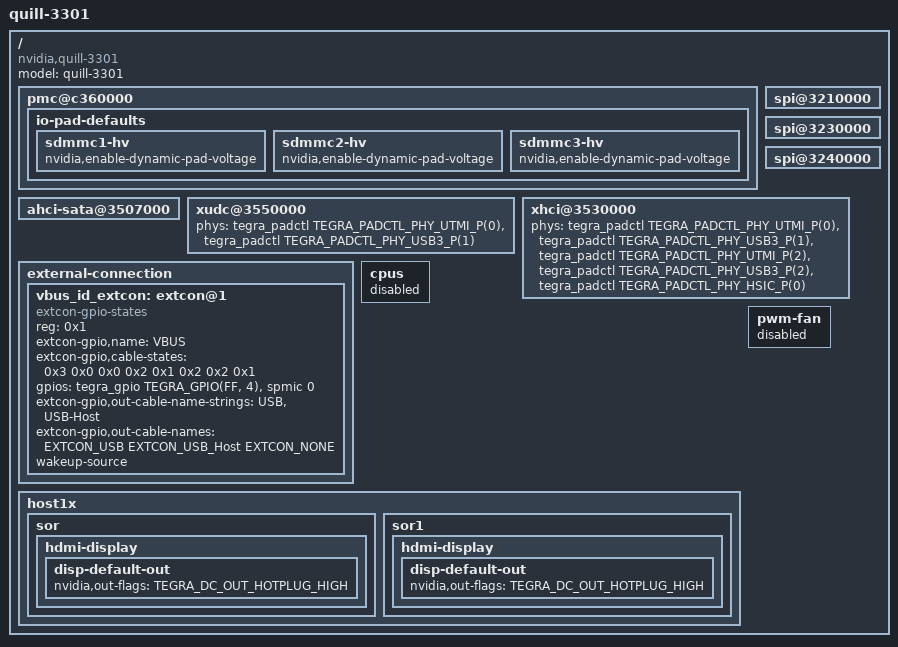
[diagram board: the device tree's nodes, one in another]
/*
 * tegra186-quill-comon-e3301-0000-a00.dtsi: Quill common dtsi.
 *
 * Copyright (c) 2015-2016, NVIDIA CORPORATION.  All rights reserved.
 *
 * This program is free software; you can redistribute it and/or modify
 * it under the terms of the GNU General Public License as published by
 * the Free Software Foundation; version 2 of the License.
 *
 * This program is distributed in the hope that it will be useful, but WITHOUT
 * ANY WARRANTY; without even the implied warranty of MERCHANTABILITY or
 * FITNESS FOR A PARTICULAR PURPOSE.  See the GNU General Public License for
 * more details.
 */

#include "tegra186-quill-common.dtsi"
#include "tegra186-quill-e3301-powermon.dtsi"
#include "tegra186-quill-pb-e3301-0000-a00-pinmux-manual.dtsi"
#include "tegra186-quill-pb-thermal.dtsi"

#define EXTCON_NONE		0
#define EXTCON_USB             1
#define EXTCON_USB_Host        2

/ {
        model = "quill-3301";
        compatible = "nvidia,quill-3301", "nvidia,tegra186";

        #address-cells = <2>;
        #size-cells = <2>;

	pmc@c360000 {
		io-pad-defaults {
			sdmmc1-hv {
				nvidia,enable-dynamic-pad-voltage;
			};
			sdmmc2-hv {
				nvidia,enable-dynamic-pad-voltage;
			};
			sdmmc3-hv {
				nvidia,enable-dynamic-pad-voltage;
			};
		};
	};

	spi@3210000 {
		status = "okay";
	};

	spi@3230000 {
		status = "okay";
	};

	spi@3240000 {
		status = "okay";
	};

	ahci-sata@3507000 {
		status = "okay";
	};

	xudc@3550000 {
		status = "okay";
		phys = <&tegra_padctl TEGRA_PADCTL_PHY_UTMI_P(0)>,
			<&tegra_padctl TEGRA_PADCTL_PHY_USB3_P(1)>;
		phy-names = "usb2", "usb3";
	};

	xhci@3530000 {
		status = "okay";
		phys = <&tegra_padctl TEGRA_PADCTL_PHY_UTMI_P(0)>,
			<&tegra_padctl TEGRA_PADCTL_PHY_USB3_P(1)>,
			<&tegra_padctl TEGRA_PADCTL_PHY_UTMI_P(2)>,
			<&tegra_padctl TEGRA_PADCTL_PHY_USB3_P(2)>,
			<&tegra_padctl TEGRA_PADCTL_PHY_HSIC_P(0)>;
		phy-names = "utmi-0", "usb3-1", "utmi-2", "usb3-2", "hsic-0";
	};

	external-connection {
		vbus_id_extcon: extcon@1 {
			compatible = "extcon-gpio-states";
			reg = <0x1>;
			extcon-gpio,name = "VBUS";
			extcon-gpio,cable-states = <0x3 0x0
						    0x0 0x2
						    0x1 0x2
						    0x2 0x1>;
			gpios = <&tegra_gpio TEGRA_GPIO(FF, 4) 0 &spmic 0 0>;
			extcon-gpio,out-cable-name-strings = "USB", "USB-Host";
			extcon-gpio,out-cable-names = <EXTCON_USB EXTCON_USB_Host EXTCON_NONE>;
			wakeup-source;
			#extcon-cells = <1>;
		};
	};

	cpus {
		status = "disabled";
	};

	host1x {
		sor {
			hdmi-display {
				disp-default-out {
					nvidia,out-flags = <TEGRA_DC_OUT_HOTPLUG_HIGH>;
				};
			};
		};

		sor1 {
			hdmi-display {
				disp-default-out {
					nvidia,out-flags = <TEGRA_DC_OUT_HOTPLUG_HIGH>;
				};
			};
		};
	};

	pwm-fan {
		status = "disabled";
	};
};

